# MKM34Z7 register map
Vendor: Freescale Semiconductor, Inc.; Series: Kinetis_M; File version: 1.6
CPU: CM0PLUS r0p0, little endian, no MPU, no FPU, VTOR, 2 interrupt priority bits
Registers are 8-bit, read-write, reset 0x0 unless marked. A register's access mark holds for its fields unless they carry their own. Offsets are from the block's base; [hi:lo] are bit positions; {n}, {i} and the like mark numbered series; 'fields as' and 'values as' point back to an identical list.

## MMAU — Memory-Mapped Arithmetic Unit
Base 0xF0004000; register names take the prefix MMAU_
{0x0+4i} X{i} 32-bit (i=0..3) — Operand Register X{i}
0x10 A0 32-bit — Accumulator Register A0
0x14 A1 32-bit — Accumulator Register A1
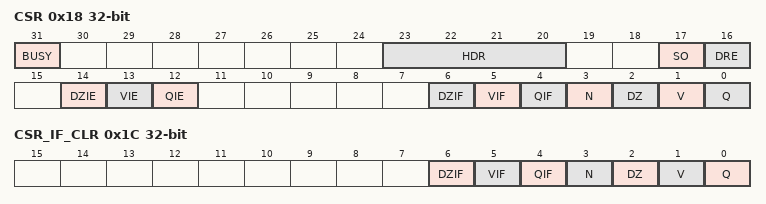
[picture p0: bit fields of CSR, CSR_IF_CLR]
0x18 CSR 32-bit — Control/Status Register
  [31] BUSY ro
    0=MMAU is idle; 1=MMAU is busy performing a divide or square root calculation
  [23:20] HDR ro — Hardware Revision Level
    0=Current Hardware Revision Level is 0000
  [17] SO — Supervisor-Only
    0=MMAU registers can be access in both User Mode or Supervisor Mode; 1=MMAU registers can only be access in Supervisor Mode
  [16] DRE — DMA Request Enable
    0=MMAU will not generate DMA request when in IDLE (not busy) state; 1=MMAU will generate DMA request when in IDLE (not busy) state
  [14] DZIE — Divide-by-Zero Interrupt Enable
    0=MMAU will not generate interrupt even CSR[DZIF]=1; 1=If CSR[DZIF] = 1, MMAU will generate an interrupt to signal a divide-by-zero
  [13] VIE — Divide/Multiply Overflow (V flag) Interrupt Enable
    0=V flag (CSR[VIF]) set will not generate interrupt; 1=V flag (CSR[VIF]) set will generate interrupt to inform a divide or multiply overflow
  [12] QIE — Accumulation Overflow (Q flag) Interrupt Enable
    0=Q flag (CSR[QIF]) set will not generate interrupt; 1=Q flag (CSR[QIF]) set will generate interrupt to inform an accumulation overflow
  [6] DZIF ro — DZ Interrupt Flag: Divide by Zero
    0=For divide, the divisor is not zero, or the calculation is not divide; 1=For divide, the divisor is zero, which is a divide-by-zero error
  [5] VIF ro — V Interrupt Flag: Multiply or Divide overflow
    0=Calculation is not include divider or multiply, or the product/quotient does not overflow; 1=Product in multiply or multiply with accumulation, or quotient of a divide overflows
  [4] QIF ro — Q Interrupt Flag: Accumulation Overflow Interrupt Status
    0=No accumulation operation or accumulation operation does not overflow; 1=Accumulation overflows during a MAC instruction
  [3] N — N flag: Signed calculation result is negative
    0=Calculation raw result is zero or positive, or unsigned number; 1=Calculation raw result is negative
  [2] DZ — DZ flag: Divide by Zero
    values as DZIF
  [1] V — V flag: Multiply or Divide overflow
    values as VIF
  [0] Q — Q flag: Accumulation Overflow
    values as QIF
0x1C CSR_IF_CLR 32-bit — CSR Interrupt Flags Clearance Register
  [6] DZIF wo — DZ Interrupt Flag: Divide by Zero
    0=Write "0" is ignored; 1=Write "1" to clear CSR[DZIF]
  [5] VIF wo — V Interrupt Flag: Multiply or Divide overflow
    0=Write "0" is ignored; 1=Write "1" to clear CSR[VIF]
  [4] QIF wo — Q Interrupt Flag: Accumulation Overflow Interrupt Status
    0=Write "0" is ignored; 1=Write "1" to clear CSR[QIF]
  [3] N wo — N flag: Signed calculation result is negative
    0=Write "0" to clear CSR[N]; 1=Write "1" to set CSR[N]
  [2] DZ wo — DZ flag: Divide by Zero
    0=Write "0" will clear CSR[DZ]; 1=Write "1" will set CSR[DZ]
  [1] V wo — V flag: Multiply or Divide overflow
    0=Write "0" will clear CSR[V]; 1=Write "1" will set CSR[V]
  [0] Q wo — Q flag: Accumulation Overflow
    0=Write "0" will clear CSR[Q]; 1=Write "1" will set CSR[Q]

## CAU — Memory Mapped Cryptographic Acceleration Unit (MMCAU)
Base 0xF0005000
{0x0+4i} CAU_DIRECT{i} 32-bit wo (i=0..15) — Direct access register {i}
  [31:0] CAU_DIRECT{i} — Direct register {i}
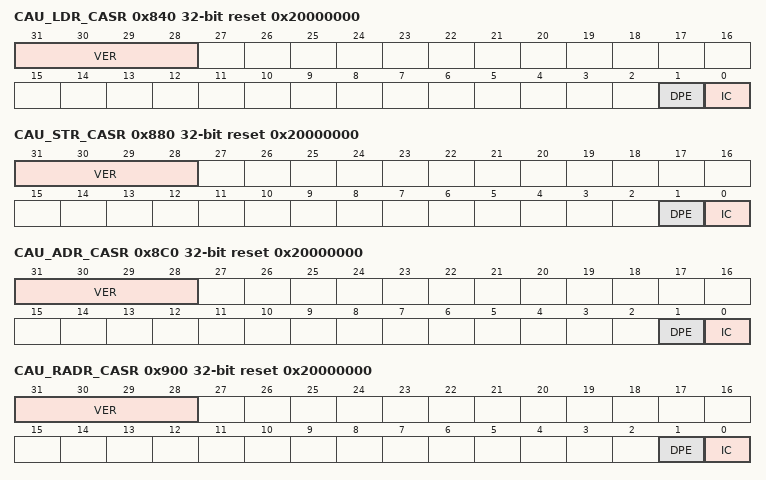
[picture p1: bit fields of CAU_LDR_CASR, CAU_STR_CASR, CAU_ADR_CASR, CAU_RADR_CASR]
0x840 CAU_LDR_CASR 32-bit wo reset 0x20000000 — Status register - Load Register command
  [31:28] VER — CAU version
    1=Initial CAU version; 2=Second version, added support for SHA-256 algorithm.(This is the value on this device)
  [1] DPE
    0=No error detected; 1=DES key parity error detected
  [0] IC
    0=No illegal commands issued; 1=Illegal command issued
0x844 CAU_LDR_CAA 32-bit wo — Accumulator register - Load Register command
  [31:0] ACC
{0x848+4i} CAU_LDR_CA{i} 32-bit wo (i=0..8) — General Purpose Register {i} - Load Register command
0x880 CAU_STR_CASR 32-bit ro reset 0x20000000 — Status register - Store Register command
  fields as CAU_LDR_CASR
0x884 CAU_STR_CAA 32-bit ro — Accumulator register - Store Register command
  [31:0] ACC
{0x888+4i} CAU_STR_CA{i} 32-bit ro (i=0..8) — General Purpose Register {i} - Store Register command
0x8C0 CAU_ADR_CASR 32-bit wo reset 0x20000000 — Status register - Add Register command
  fields as CAU_LDR_CASR
0x8C4 CAU_ADR_CAA 32-bit wo — Accumulator register - Add to register command
  [31:0] ACC
{0x8C8+4i} CAU_ADR_CA{i} 32-bit wo (i=0..8) — General Purpose Register {i} - Add to register command
0x900 CAU_RADR_CASR 32-bit wo reset 0x20000000 — Status register - Reverse and Add to Register command
  fields as CAU_LDR_CASR
0x904 CAU_RADR_CAA 32-bit wo — Accumulator register - Reverse and Add to Register command
  [31:0] ACC
{0x908+4i} CAU_RADR_CA{i} 32-bit wo (i=0..8) — General Purpose Register {i} - Reverse and Add to Register command
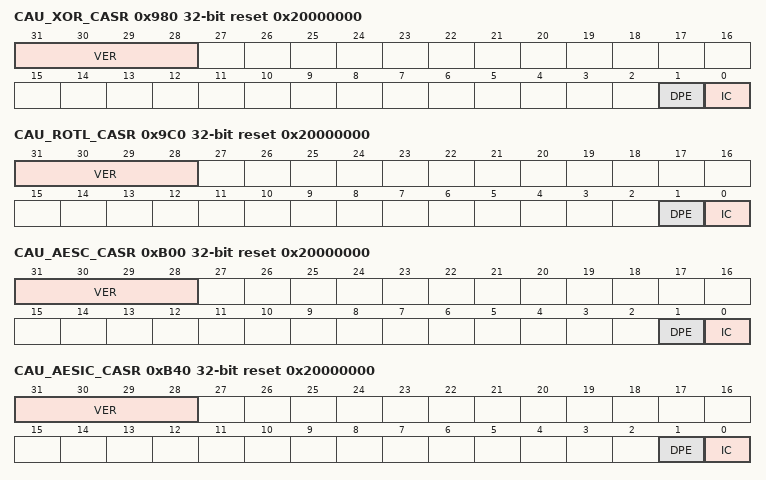
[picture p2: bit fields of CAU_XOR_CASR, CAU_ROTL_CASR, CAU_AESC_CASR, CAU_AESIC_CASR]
0x980 CAU_XOR_CASR 32-bit wo reset 0x20000000 — Status register - Exclusive Or command
  fields as CAU_LDR_CASR
0x984 CAU_XOR_CAA 32-bit wo — Accumulator register - Exclusive Or command
  [31:0] ACC
{0x988+4i} CAU_XOR_CA{i} 32-bit wo (i=0..8) — General Purpose Register {i} - Exclusive Or command
0x9C0 CAU_ROTL_CASR 32-bit wo reset 0x20000000 — Status register - Rotate Left command
  fields as CAU_LDR_CASR
0x9C4 CAU_ROTL_CAA 32-bit wo — Accumulator register - Rotate Left command
  [31:0] ACC
{0x9C8+4i} CAU_ROTL_CA{i} 32-bit wo (i=0..8) — General Purpose Register {i} - Rotate Left command
0xB00 CAU_AESC_CASR 32-bit wo reset 0x20000000 — Status register - AES Column Operation command
  fields as CAU_LDR_CASR
0xB04 CAU_AESC_CAA 32-bit wo — Accumulator register - AES Column Operation command
  [31:0] ACC
{0xB08+4i} CAU_AESC_CA{i} 32-bit wo (i=0..8) — General Purpose Register {i} - AES Column Operation command
0xB40 CAU_AESIC_CASR 32-bit wo reset 0x20000000 — Status register - AES Inverse Column Operation command
  fields as CAU_LDR_CASR
0xB44 CAU_AESIC_CAA 32-bit wo — Accumulator register - AES Inverse Column Operation command
  [31:0] ACC
{0xB48+4i} CAU_AESIC_CA{i} 32-bit wo (i=0..8) — General Purpose Register {i} - AES Inverse Column Operation command
